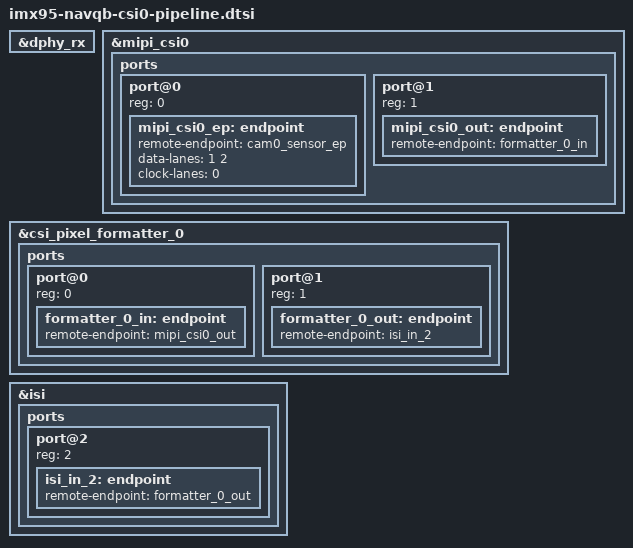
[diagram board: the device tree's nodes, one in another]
// SPDX-License-Identifier: (GPL-2.0+ OR MIT)
/*
 * Copyright 2026 NXP
 *
 * Shared MIPI CSI0 capture pipeline for NavQ-B port A (camera-only 22-pin
 * connector): sensor -> DPHY-RX/CSI0 -> CSI pixel formatter 0 -> ISI port 2.
 * A camera overlay includes this file and provides a "cam0_sensor_ep"
 * endpoint on its sensor node.
 */

&dphy_rx {
	status = "okay";
};

&mipi_csi0 {
	status = "okay";

	ports {
		#address-cells = <1>;
		#size-cells = <0>;

		port@0 {
			reg = <0>;
			mipi_csi0_ep: endpoint {
				remote-endpoint = <&cam0_sensor_ep>;
				data-lanes = <1 2>;
				clock-lanes = <0>;
			};
		};

		port@1 {
			reg = <1>;
			mipi_csi0_out: endpoint {
				remote-endpoint = <&formatter_0_in>;
			};
		};
	};
};

&csi_pixel_formatter_0 {
	status = "okay";

	ports {
		#address-cells = <1>;
		#size-cells = <0>;

		port@0 {
			reg = <0>;
			formatter_0_in: endpoint {
				remote-endpoint = <&mipi_csi0_out>;
			};
		};

		port@1 {
			reg = <1>;
			formatter_0_out: endpoint {
				remote-endpoint = <&isi_in_2>;
			};
		};
	};
};

&isi {
	status = "okay";

	ports {
		#address-cells = <1>;
		#size-cells = <0>;

		port@2 {
			reg = <2>;
			isi_in_2: endpoint {
				remote-endpoint = <&formatter_0_out>;
			};
		};
	};
};
